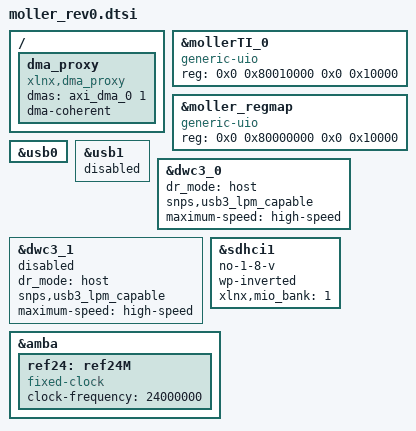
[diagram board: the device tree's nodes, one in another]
/ {
    dma_proxy {
        compatible = "xlnx,dma_proxy";
        dmas = <&axi_dma_0 1>;
        dma-names = "dma_proxy_rx";
		dma-coherent;
    };
};

&mollerTI_0 {
	compatible = "generic-uio";
	reg = <0x0 0x80010000 0x0 0x10000>;
};

&moller_regmap{
	compatible = "generic-uio";
	reg = <0x0 0x80000000 0x0 0x10000>;
};

&usb0 {
	status = "okay";
};

&usb1 {
	status = "disabled";
};

&dwc3_0 {
	status = "okay";
	dr_mode = "host";
	snps,usb3_lpm_capable;
	maximum-speed = "high-speed";
};

&dwc3_1 {
	status = "disabled";
	dr_mode = "host";
	snps,usb3_lpm_capable;
	maximum-speed = "high-speed";
};

/* SD1 with level shifter */
&sdhci1 {
	status = "okay";
	no-1-8-v;	/* for 1.0 silicon */
	wp-inverted;
	xlnx,mio_bank = <1>;
};

&amba {
	ref24: ref24M {
		compatible = "fixed-clock";
		#clock-cells = <0>;
		clock-frequency = <24000000>;
	};
};
